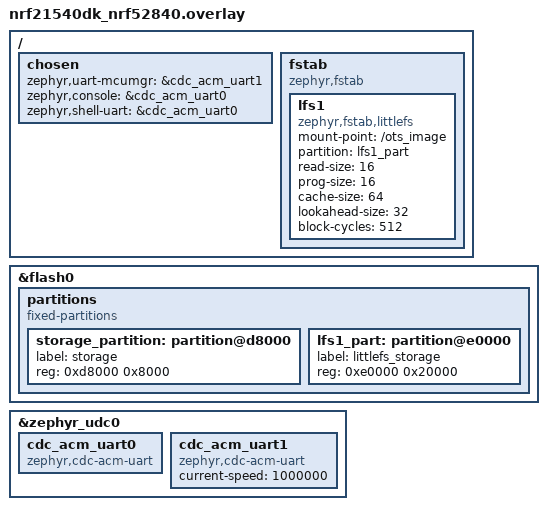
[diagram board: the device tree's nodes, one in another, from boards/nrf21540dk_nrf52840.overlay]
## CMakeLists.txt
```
#
# Copyright (c) 2022 Nordic Semiconductor
#
# SPDX-License-Identifier: LicenseRef-Nordic-5-Clause
#

cmake_minimum_required(VERSION 3.20.0)

# The application uses the conf/<board> scheme for configuration files.
#set(APPLICATION_CONFIG_DIR "${CMAKE_CURRENT_SOURCE_DIR}/conf/\${BOARD}")

set(PM_STATIC_YML_FILE
  #"${CMAKE_CURRENT_SOURCE_DIR}/conf/\${BOARD}/pm_static_${BOARD}.yml"
   ${CMAKE_CURRENT_SOURCE_DIR}/boards/pm_static_${BOARD}.yml
  )

list(APPEND hci_rpmsg_b0n_OVERLAY_CONFIG overlay-minimal-size.conf)

find_package(Zephyr REQUIRED HINTS $ENV{ZEPHYR_BASE})
project(central_esl)

# NORDIC SDK APP START
target_sources(app PRIVATE
  src/main.c
)

# Add ESLS Client source
zephyr_library_sources_ifdef(
  CONFIG_BT_ESL_CLIENT
  ../service/esl_client.c
  ../service/esl_client_settings.c
  ../service/esl_common.c)

zephyr_library_sources_ifdef(
  CONFIG_ESL_CLIENT_SHELL
  ../service/esl_client_shell.c
  ../service/esl_dummy_cmd.c)
zephyr_library_sources_ifdef(CONFIG_BT_ESL_TAG_STORAGE  ../service/esl_client_tag_storage.c)

zephyr_library_include_directories_ifdef(CONFIG_BT_ESL_CLIENT ../service)
target_include_directories(app PRIVATE   ${ZEPHYR_BASE}/subsys/bluetooth/host)

# NORDIC SDK APP END

zephyr_library_include_directories(.)
```

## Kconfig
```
#
# Copyright (c) 2022 Nordic Semiconductor
#
# SPDX-License-Identifier: LicenseRef-Nordic-5-Clause
#

source "Kconfig.zephyr"

menu "Nordic ESL BLE GATT service client"

config BT_ESL_CLIENT_THREAD_STACK_SIZE
	int "Thread stack size"
	default 1024
	help
	  Stack size used in each of the two threads

config BT_ESL_SECURITY_ENABLED
	bool "Enable security"
	select BT_SMP
	select BT_BONDABLE
	select BT_BONDING_REQUIRED
	help
	  "Enable BLE security for the ESL service"

config BT_ESL_AP_AUTO_MODE
	bool "AP auto onboarding Tag mode"
	help
	  "Enable,AP will auto scan and configure tag. Disable,AP will only accept shell command"

if BT_ESL_AP_AUTO_MODE
config BT_ESL_AP_AUTO_TAG_PER_GROUP
	int "Tag per group"
	default ESL_CLIENT_MAX_RESPONSE_SLOT_BUFFER
	help
	  "How many tags should keep in same group for auto onboarding.
	   Tag number exceeds this number should be in next group.
	   Otherwise, response key is not enough for all tags in same group.
	   How to choose this number depends on what scenario we want to show.
	   Less or equal to ESL_CLIENT_MAX_RESPONSE_SLOT_BUFFER demostrates decrypts response EAD on-the-fly.
	   Greater than ESL_CLIENT_MAX_RESPONSE_SLOT_BUFFER demostrates ESL AP able to control large amount of tags at the same time."

config BT_ESL_AP_GROUP_PER_BUTTON
	int "Group per button"
	default 3
	help
	  "How many groups should be controlled by one button.
	   If this number is greater than 1, AP will control multiple groups by one button.
	   Otherwise, AP will control one group by one button."
endif

config BT_ESL_AP_AUTO_PAST_TAG
	bool "AP auto past mode"
	help
	  "Enable,AP will auto send update complete command and PAST to unsynchronized tag. Disable,AP will only accept shell command"

config BT_ESL_AP_PTS
	bool "ESL access point for PTS test"
	help
	  Enable PTS test for ESL access point

module = CENTRAL_ESL
module-str = central esl
source "${ZEPHYR_BASE}/subsys/logging/Kconfig.template.log_config"
endmenu

rsource "../service/Kconfig.esl_client"
```

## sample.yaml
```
sample:
  name: BLE ESL AP
  description: Bluetooth Low Energy ESL Access Point application
tests:
  applications.bluetooth.central_esl:
    build_only: true
    platform_allow: nrf52840dk_nrf52840 nrf5340dk_nrf5340_cpuapp thingy53_nrf5340_cpuapp
    integration_platforms:
      - nrf52840dk_nrf52840
      - nrf5340dk_nrf5340_cpuapp
      - thingy53_nrf5340_cpuapp
    tags: bluetooth ci_build
```

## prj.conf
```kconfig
#
# Copyright (c) 2022 Nordic Semiconductor
#
# SPDX-License-Identifier: LicenseRef-Nordic-5-Clause
#

CONFIG_DK_LIBRARY=y
CONFIG_NEWLIB_LIBC=y
CONFIG_GPIO=y

# Enable the UART driver
CONFIG_CONSOLE=y
CONFIG_UART_CONSOLE=y

# Enable the BLE stack with GATT Client configuration
CONFIG_BT=y
CONFIG_BT_CENTRAL=y
CONFIG_BT_PERIPHERAL=n
CONFIG_BT_GATT_CLIENT=y
CONFIG_BT_MAX_CONN=4
CONFIG_BT_MAX_PAIRED=4

# Enable ESL Client modules
CONFIG_BT_ESL_CLIENT=y
CONFIG_BT_ESL_AP_AUTO_MODE=y
CONFIG_BT_ESL_DEMO_SECURITY=n

CONFIG_BT_ESL_SECURITY_ENABLED=y
CONFIG_BT_ESL_AP_AUTO_PAST_TAG=y

# Enable the BLE modules from NCS
CONFIG_BT_SCAN=y
CONFIG_BT_SCAN_FILTER_ENABLE=y
CONFIG_BT_SCAN_UUID_CNT=1
CONFIG_BT_GATT_DM=y
CONFIG_HEAP_MEM_POOL_SIZE=4096
CONFIG_BT_SCAN_ADDRESS_CNT=16

# Enable EATT for multi read/write request
CONFIG_BT_L2CAP_ECRED=y
CONFIG_BT_EATT=y
CONFIG_BT_ATT_PREPARE_COUNT=32
CONFIG_BT_EATT_MAX=16
CONFIG_BT_GATT_AUTO_SEC_REQ=n
CONFIG_BT_EATT_AUTO_CONNECT=n
CONFIG_BT_GATT_SERVICE_CHANGED=n
CONFIG_BT_GATT_DYNAMIC_DB=n

CONFIG_BT_L2CAP_TX_MTU=498
CONFIG_BT_OTS_L2CAP_CHAN_TX_MTU=498
# This example requires more workqueue stack
CONFIG_SYSTEM_WORKQUEUE_STACK_SIZE=4096

# Settings need more memory
CONFIG_MAIN_STACK_SIZE=2048

# Enable bonding
CONFIG_BT_SETTINGS=y
CONFIG_FLASH=y
CONFIG_FLASH_PAGE_LAYOUT=y
CONFIG_FLASH_MAP=y
CONFIG_NVS=y
CONFIG_BT_BONDABLE=y
CONFIG_BT_ESL_TAG_STORAGE=y

# Bluetooth L2CAP parameter
CONFIG_BT_L2CAP_TX_BUF_COUNT=12

# LOG
CONFIG_LOG=y
CONFIG_LOG_BACKEND_UART=n
CONFIG_SHELL_LOG_BACKEND=n
CONFIG_USE_SEGGER_RTT=y
CONFIG_LOG_BACKEND_RTT=y
CONFIG_LOG_BUFFER_SIZE=8192
CONFIG_LOG_BACKEND_RTT_MODE_DROP=n
CONFIG_LOG_PRINTK=n
CONFIG_SEGGER_RTT_BUFFER_SIZE_UP=8192

# SHELL
CONFIG_SHELL_PROMPT_UART="ESL_AP:~$ "
CONFIG_SHELL_STACK_SIZE=4096
CONFIG_ESL_CLIENT_SHELL=y
CONFIG_SHELL_ARGC_MAX=48
CONFIG_SHELL_BACKEND_SERIAL_TX_RING_BUFFER_SIZE=24

# Periodic Adv
CONFIG_BT_EXT_ADV=y
CONFIG_BT_PER_ADV=y
CONFIG_BT_LOG_SNIFFER_INFO=y
CONFIG_BT_EXT_ADV_LEGACY_SUPPORT=y
CONFIG_BT_PER_ADV_SYNC=y
CONFIG_BT_DEVICE_NAME="ESL_AP"
CONFIG_BT_EXT_ADV_MAX_ADV_SET=1

CONFIG_BT_AUTO_PHY_UPDATE=n
CONFIG_BT_BUF_CMD_TX_COUNT=20
CONFIG_ESL_CLIENT_DEFAULT_ESL_ID=0
CONFIG_ESL_CLIENT_DEFAULT_GROUP_ID=0
CONFIG_BT_ESL_MAX_QUEUED_TIMED_COMMANDS=1

# Enable mcumgr
CONFIG_ZCBOR=y
CONFIG_MCUMGR=y
# Required by the `taskstat` command
CONFIG_THREAD_MONITOR=y
# USB backend is serial device
CONFIG_BASE64=y
CONFIG_MCUMGR_TRANSPORT_UART=y
CONFIG_USB_CDC_ACM_LOG_LEVEL_OFF=y
# Support for taskstat command
CONFIG_MCUMGR_GRP_OS_TASKSTAT=y

# Enable statistics and statistic names
CONFIG_STATS=y
CONFIG_STATS_NAMES=y

# Enable most core commands
CONFIG_STREAM_FLASH=y
CONFIG_IMG_MANAGER=y
CONFIG_MCUMGR_GRP_IMG=y
CONFIG_MCUMGR_GRP_OS=y
CONFIG_MCUMGR_GRP_STAT=y
# Enable file system commands
CONFIG_MCUMGR_GRP_FS=y

# Debug
CONFIG_BT_ESL_CLIENT_LOG_LEVEL_INF=y
CONFIG_CENTRAL_ESL_LOG_LEVEL_INF=y
# CONFIG_BT_USE_DEBUG_KEYS=y
# CONFIG_BT_STORE_DEBUG_KEYS=y

CONFIG_BT_KEYS_OVERWRITE_OLDEST=y
# Response slot 8 need 546 bytes to accept response key
# CONFIG_SHELL_BACKEND_SERIAL_RX_RING_BUFFER_SIZE=546
# CONFIG_SHELL_CMD_BUFF_SIZE=546
# Response slot 12 need 742 bytes to accept response key
# CONFIG_SHELL_BACKEND_SERIAL_RX_RING_BUFFER_SIZE=742
# CONFIG_SHELL_CMD_BUFF_SIZE=742
# Response slot 23 need 1282 bytes to accept response key
CONFIG_SHELL_BACKEND_SERIAL_RX_RING_BUFFER_SIZE=1282
CONFIG_SHELL_CMD_BUFF_SIZE=1282
CONFIG_SETTINGS_SHELL=y
CONFIG_SHELL_LOG_BACKEND=n
CONFIG_DEVICE_SHELL=n
CONFIG_DEVMEM_SHELL=n
CONFIG_FLASH_SHELL=n
CONFIG_BT_DEBUG_LOG=y
CONFIG_BT_DEBUG_HCI_CORE=n
CONFIG_BT_DEBUG_HCI_DRIVER=n
CONFIG_BT_GATT_DM_LOG_LEVEL_DBG=n
CONFIG_BT_GATT_DM_MAX_ATTRS=256
CONFIG_BT_DEBUG_GATT=n
CONFIG_ASSERT=n

# BTMON hci log start
# CONFIG_BT_DEBUG_MONITOR_UART=y
# CONFIG_UART_CONSOLE=n
# BTMON hci log end
```

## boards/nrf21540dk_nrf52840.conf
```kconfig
#
# Copyright (c) 2023 Nordic Semiconductor ASA
#
# SPDX-License-Identifier: LicenseRef-Nordic-5-Clause
#

# External Flash for TAG OTS image storage
# Need this when storage is on flash
CONFIG_MPU_ALLOW_FLASH_WRITE=y

CONFIG_FLASH=y
CONFIG_FLASH_MAP=y
CONFIG_FLASH_PAGE_LAYOUT=y
CONFIG_FILE_SYSTEM=y
CONFIG_FILE_SYSTEM_LITTLEFS=y
CONFIG_FILE_SYSTEM_SHELL=y
CONFIG_RESET_ON_FATAL_ERROR=n
CONFIG_ESL_CLIENT_MAX_GROUP=64

# ESL AP two CDC uart, one for command, one for SMP
CONFIG_USB_DEVICE_STACK=y
CONFIG_USB_DEVICE_PRODUCT="Nordic ESL Access Point"
CONFIG_UART_LINE_CTRL=y

# LOG
# CONFIG_MCUBOOT_UTIL_LOG_LEVEL_WRN=y
# CONFIG_MCUMGR_LOG_LEVEL_DBG=y
# CONFIG_BT_DEBUG_OTS_CLIENT=y
# CONFIG_BT_OTS_CLIENT_LOG_LEVEL_DBG=y

# PAWR timing
CONFIG_BT_CTLR_SDC_PAWR_ADV_COUNT=1
CONFIG_BT_CTLR_SDC_PERIODIC_ADV_RSP_TX_BUFFER_COUNT=3
CONFIG_BT_CTLR_SDC_PERIODIC_ADV_RSP_RX_BUFFER_COUNT=12
CONFIG_BT_PER_ADV_SYNC_MAX=1
CONFIG_BT_CTLR_SDC_MAX_CONN_EVENT_LEN_DEFAULT=2500
CONFIG_BT_BUF_ACL_RX_SIZE=502
CONFIG_BT_BUF_CMD_TX_SIZE=255
CONFIG_BT_BUF_EVT_DISCARDABLE_SIZE=255
CONFIG_BT_CTLR_SDC_PERIPHERAL_COUNT=0
CONFIG_BT_CTLR_ADV_DATA_LEN_MAX=73
CONFIG_BT_CTLR_TX_PWR_PLUS_8=y
```

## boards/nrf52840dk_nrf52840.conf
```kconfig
#
# Copyright (c) 2023 Nordic Semiconductor ASA
#
# SPDX-License-Identifier: LicenseRef-Nordic-5-Clause
#

# External Flash for TAG OTS image storage
# Need this when storage is on flash
CONFIG_MPU_ALLOW_FLASH_WRITE=y

# Need this when storage is on MX25R64 QSPI
CONFIG_NORDIC_QSPI_NOR=y
CONFIG_NORDIC_QSPI_NOR_FLASH_LAYOUT_PAGE_SIZE=4096
CONFIG_FLASH=y
CONFIG_FLASH_MAP=y
CONFIG_FLASH_PAGE_LAYOUT=y
CONFIG_FILE_SYSTEM=y
CONFIG_FILE_SYSTEM_LITTLEFS=y
CONFIG_PM_PARTITION_REGION_LITTLEFS_EXTERNAL=y
CONFIG_PM_PARTITION_SIZE_LITTLEFS=0x300000
CONFIG_FILE_SYSTEM_SHELL=y
CONFIG_RESET_ON_FATAL_ERROR=n
CONFIG_ESL_CLIENT_MAX_GROUP=64

# ESL AP two CDC uart, one for command, one for SMP
CONFIG_USB_DEVICE_STACK=y
CONFIG_USB_DEVICE_PRODUCT="Nordic ESL Access Point"
CONFIG_UART_LINE_CTRL=y

# Ensure an MCUboot-compatible binary is generated
CONFIG_BOOTLOADER_MCUBOOT=y

# LOG
# CONFIG_MCUBOOT_UTIL_LOG_LEVEL_WRN=y
# CONFIG_MCUMGR_LOG_LEVEL_DBG=y
# CONFIG_BT_DEBUG_OTS_CLIENT=y
# CONFIG_BT_OTS_CLIENT_LOG_LEVEL_DBG=y

# PAWR timing
CONFIG_BT_CTLR_SDC_PAWR_ADV_COUNT=1
CONFIG_BT_CTLR_SDC_PERIODIC_ADV_RSP_TX_BUFFER_COUNT=3
CONFIG_BT_CTLR_SDC_PERIODIC_ADV_RSP_RX_BUFFER_COUNT=12
CONFIG_BT_PER_ADV_SYNC_MAX=1
CONFIG_BT_CTLR_SDC_MAX_CONN_EVENT_LEN_DEFAULT=2500
CONFIG_BT_BUF_ACL_RX_SIZE=502
CONFIG_BT_BUF_CMD_TX_SIZE=255
CONFIG_BT_BUF_EVT_DISCARDABLE_SIZE=255
CONFIG_BT_CTLR_SDC_PERIPHERAL_COUNT=0
CONFIG_BT_CTLR_ADV_DATA_LEN_MAX=73
CONFIG_BT_CTLR_TX_PWR_PLUS_8=y
```

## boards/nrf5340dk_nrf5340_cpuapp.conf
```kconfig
#
# Copyright (c) 2023 Nordic Semiconductor ASA
#
# SPDX-License-Identifier: LicenseRef-Nordic-5-Clause
#

# External Flash for TAG OTS image storage
# Need this when storage is on flash
CONFIG_MPU_ALLOW_FLASH_WRITE=y

# Need this when storage is on MX25R64 QSPI
CONFIG_NORDIC_QSPI_NOR=y
CONFIG_NORDIC_QSPI_NOR_FLASH_LAYOUT_PAGE_SIZE=4096
CONFIG_FLASH=y
CONFIG_FLASH_MAP=y
CONFIG_FLASH_PAGE_LAYOUT=y
CONFIG_FILE_SYSTEM=y
CONFIG_FILE_SYSTEM_LITTLEFS=y
CONFIG_PM_PARTITION_REGION_LITTLEFS_EXTERNAL=y
CONFIG_PM_PARTITION_SIZE_LITTLEFS=0x300000
CONFIG_FILE_SYSTEM_SHELL=y
CONFIG_RESET_ON_FATAL_ERROR=n

# ESL AP two CDC uart, one for command, one for SMP
CONFIG_USB_DEVICE_STACK=y
CONFIG_USB_DEVICE_PRODUCT="Nordic ESL Access Point"
CONFIG_UART_LINE_CTRL=y

# Ensure an MCUboot-compatible binary is generated
CONFIG_BOOTLOADER_MCUBOOT=y

# LOG
# CONFIG_MCUBOOT_UTIL_LOG_LEVEL_WRN=y
# CONFIG_MCUMGR_LOG_LEVEL_DBG=y
# CONFIG_BT_DEBUG_OTS_CLIENT=y
# CONFIG_BT_OTS_CLIENT_LOG_LEVEL_DBG=y
```

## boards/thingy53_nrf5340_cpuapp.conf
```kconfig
#
# Copyright (c) 2023 Nordic Semiconductor ASA
#
# SPDX-License-Identifier: LicenseRef-Nordic-5-Clause
#

# External Flash for TAG OTS image storage
# Need this when storage is on flash
CONFIG_MPU_ALLOW_FLASH_WRITE=y

# Need this when storage is on MX25R64 QSPI
CONFIG_NORDIC_QSPI_NOR=y
CONFIG_NORDIC_QSPI_NOR_FLASH_LAYOUT_PAGE_SIZE=4096
CONFIG_FLASH=y
CONFIG_FLASH_MAP=y
CONFIG_FLASH_PAGE_LAYOUT=y
CONFIG_FILE_SYSTEM=y
CONFIG_FILE_SYSTEM_LITTLEFS=y
CONFIG_FILE_SYSTEM_SHELL=y
CONFIG_RESET_ON_FATAL_ERROR=n

# ESL AP two CDC uart, one for command, one for SMP
CONFIG_USB_DEVICE_STACK=y
CONFIG_USB_DEVICE_PRODUCT="Nordic ESL Access Point"
CONFIG_UART_LINE_CTRL=y
CONFIG_USB_DEVICE_INITIALIZE_AT_BOOT=y

# # Ensure an MCUboot-compatible binary is generated
CONFIG_BOOTLOADER_MCUBOOT=y

# Enable logging
# CONFIG_MCUBOOT_UTIL_LOG_LEVEL_WRN=y
# CONFIG_MCUMGR_LOG_LEVEL_DBG=y
# CONFIG_BT_DEBUG_OTS_CLIENT=y
# CONFIG_BT_OTS_CLIENT_LOG_LEVEL_DBG=y
```

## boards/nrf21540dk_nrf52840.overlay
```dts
 / {
	chosen {
		zephyr,uart-mcumgr = &cdc_acm_uart1;
		zephyr,console = &cdc_acm_uart0;
		zephyr,shell-uart = &cdc_acm_uart0;
	};
};

/delete-node/ &storage_partition;
/ {
	fstab {
		compatible = "zephyr,fstab";
		lfs1: lfs1 {
			compatible = "zephyr,fstab,littlefs";
			mount-point = "/ots_image";
			partition = <&lfs1_part>;
			read-size = <16>;
			prog-size = <16>;
			cache-size = <64>;
			lookahead-size = <32>;
			block-cycles = <512>;
		};
	};
};


&flash0 {
	partitions {
		compatible = "fixed-partitions";
		#address-cells = <1>;
		#size-cells = <1>;
		storage_partition: partition@d8000 {
			label = "storage";
			reg = < 0xd8000 0x8000 >;
		};
		lfs1_part: partition@e0000 {
			label = "littlefs_storage";
			reg = <0xe0000 0x20000>;
		};
	};
};


&zephyr_udc0 {
	cdc_acm_uart0: cdc_acm_uart0 {
		compatible = "zephyr,cdc-acm-uart";
	};

	cdc_acm_uart1: cdc_acm_uart1 {
		current-speed=<1000000>;
		compatible = "zephyr,cdc-acm-uart";
	};

};
```

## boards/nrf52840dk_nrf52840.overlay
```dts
/ {
	chosen {
		nordic,pm-ext-flash = &mx25r64;
		zephyr,uart-mcumgr = &cdc_acm_uart1;
		zephyr,console = &cdc_acm_uart0;
		zephyr,shell-uart = &cdc_acm_uart0;
	};
};

/ {
	fstab {
		compatible = "zephyr,fstab";
		lfs1: lfs1 {
			compatible = "zephyr,fstab,littlefs";
			mount-point = "/ots_image";
			partition = <&lfs1_part>;
			read-size = <16>;
			prog-size = <16>;
			cache-size = <64>;
			lookahead-size = <32>;
			block-cycles = <512>;
		};
	};
};

&mx25r64 {
	partitions {
		compatible = "fixed-partitions";
		#address-cells = <1>;
		#size-cells = <1>;

		lfs1_part: partition@0 {
			label = "littlefs_storage";
			reg = <0x00000000 0x00100000>;
		};
	};
};

&zephyr_udc0 {
	cdc_acm_uart0: cdc_acm_uart0 {
		compatible = "zephyr,cdc-acm-uart";
	};

	cdc_acm_uart1: cdc_acm_uart1 {
		current-speed=<1000000>;
		compatible = "zephyr,cdc-acm-uart";
	};

};
```

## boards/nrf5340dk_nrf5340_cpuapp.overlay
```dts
/ {
	chosen {
		nordic,pm-ext-flash = &mx25r64;
		zephyr,uart-mcumgr = &cdc_acm_uart1;
		zephyr,console = &cdc_acm_uart0;
		zephyr,shell-uart = &cdc_acm_uart0;
	};
};

&zephyr_udc0 {
	cdc_acm_uart0: cdc_acm_uart0 {
		compatible = "zephyr,cdc-acm-uart";
	};

	cdc_acm_uart1: cdc_acm_uart1 {
		current-speed=<1000000>;
		compatible = "zephyr,cdc-acm-uart";
	};

};
```

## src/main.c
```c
/*
 * Copyright (c) 2023 Nordic Semiconductor ASA
 *
 * SPDX-License-Identifier: LicenseRef-Nordic-5-Clause
 */

/** @file
 *  @brief Nordic ESL Service Client Application
 */

#include <errno.h>
#include <zephyr/kernel.h>
#include <zephyr/sys/byteorder.h>
#include <zephyr/sys/printk.h>

#include <zephyr/bluetooth/bluetooth.h>
#include <zephyr/bluetooth/hci.h>
#include <zephyr/bluetooth/conn.h>
#include <zephyr/bluetooth/uuid.h>
#include <zephyr/bluetooth/gatt.h>
#include <zephyr/sys/slist.h>
#include <zephyr/settings/settings.h>
#include <zephyr/logging/log.h>
#include <zephyr/usb/usb_device.h>
#include <bluetooth/gatt_dm.h>
#include <bluetooth/scan.h>
#include <dk_buttons_and_leds.h>

#include "esl_client.h"

LOG_MODULE_REGISTER(central_esl, CONFIG_CENTRAL_ESL_LOG_LEVEL);

static struct bt_esl_client esl_client;

#ifdef CONFIG_MCUMGR_GRP_FS
#include <zephyr/device.h>
#include <zephyr/fs/fs.h>
#include <zephyr/fs/littlefs.h>

#define PARTITION_NODE DT_NODELABEL(lfs1)

#if DT_NODE_EXISTS(PARTITION_NODE)
/* Internal flash use DTS partition */
FS_FSTAB_DECLARE_ENTRY(PARTITION_NODE);
#else
/* External flash use PM partition */
#define STORAGE_PARTITION_LABEL littlefs_storage
#define STORAGE_PARTITION_ID	FIXED_PARTITION_ID(STORAGE_PARTITION_LABEL)

FS_LITTLEFS_DECLARE_DEFAULT_CONFIG(cstorage);
static struct fs_mount_t pm_littlefs_mnt = {.type = FS_LITTLEFS,
					    .fs_data = &cstorage,
					    .storage_dev = (void *)STORAGE_PARTITION_ID,
					    .mnt_point = MNT_POINT};
#endif /* (DT_NODE_EXISTS(PARTITION_NODE)) */
struct fs_mount_t *mp =
#if DT_NODE_EXISTS(PARTITION_NODE)
	&FS_FSTAB_ENTRY(PARTITION_NODE)
#else
	&pm_littlefs_mnt
#endif /* (DT_NODE_EXISTS(PARTITION_NODE)*/
	;
#endif /* (CONFIG_MCUMGR_GRP_FS) */
int ap_image_storage_init(void)
{
	int err = 0;
#ifdef CONFIG_MCUMGR_GRP_FS
	err = fs_mount(mp);
	if (err < 0) {
		LOG_ERR("Error mounting littlefs [%d]", err);
	}
#if defined(CONFIG_BT_ESL_TAG_STORAGE)
	struct fs_dir_t dirp;

	load_all_tags_in_storage(BIT(ESL_GROUPID_RFU_BIT));

	/* Check if TAG_BLE_ADDR_ROOT exists */
	fs_dir_t_init(&dirp);
	err = fs_opendir(&dirp, TAG_BLE_ADDR_ROOT);
	if (err) {
		err = fs_mkdir(TAG_BLE_ADDR_ROOT);
		if (err) {
			LOG_ERR("Create TAG_BLE_ADDR_ROOT dir failed (ret %d)", err);
			err = -EIO;
		}
	}

	fs_closedir(&dirp);

	/* Check if TAG_ESL_ADDR_ROOT exists */
	fs_dir_t_init(&dirp);
	err = fs_opendir(&dirp, TAG_ESL_ADDR_ROOT);
	if (err) {
		err = fs_mkdir(TAG_ESL_ADDR_ROOT);
		if (err) {
			LOG_ERR("Create TAG_ESL_ADDR_ROOT dir failed (ret %d)", err);
			err = -EIO;
		}
	}

	fs_closedir(&dirp);

#endif /* (CONFIG_BT_ESL_TAG_STORAGE) */

#else
	LOG_ERR("No valid image storage");
	err = -ENXIO;
#endif /* (CONFIG_MCUMGR_GRP_FS) */
	return err;
}

ssize_t ap_read_img_size_from_storage(uint8_t *img_path)
{
	int ret = 0;
#ifdef CONFIG_MCUMGR_GRP_FS
	/* Here demostrates how to retrieve image size from littlefs */
	struct fs_dirent dirent;
	struct fs_file_t file;
	int rc;

	fs_file_t_init(&file);
	rc = fs_open(&file, img_path, FS_O_CREATE | FS_O_RDWR);
	if (rc < 0) {
		LOG_ERR("FAIL: open %s: %d", img_path, rc);
		return 0;
	}

	rc = fs_stat(img_path, &dirent);
	if (rc < 0) {
		LOG_ERR("FAIL: stat %s: %d", img_path, rc);
		return 0;
	}

	LOG_INF("%s img_path size %d", img_path, dirent.size);
	ret = dirent.size;
	(void)fs_close(&file);
#else
	LOG_ERR("No valid image");
#endif
	return ret;
}

int ap_read_img_from_storage(uint8_t *img_path, void *data, size_t *len)
{
	int ret;
#ifdef CONFIG_MCUMGR_GRP_FS
	/* Here demostrates how to retrieve image from littlefs */
	struct fs_dirent dirent;
	struct fs_file_t file;
	int rc;

	fs_file_t_init(&file);
	rc = fs_open(&file, img_path, FS_O_CREATE | FS_O_RDWR);
	if (rc < 0) {
		LOG_ERR("FAIL: open %s: %d", img_path, rc);
		return rc;
	}

	rc = fs_stat(img_path, &dirent);
	if (rc < 0) {
		LOG_ERR("FAIL: stat %s: %d", img_path, rc);
		goto out;
	}

	if (rc == 0 && dirent.type == FS_DIR_ENTRY_FILE && dirent.size == 0) {
		LOG_ERR("Image file: %s not found", img_path);
		ret = -ENXIO;
	}

	LOG_INF("%s img_path size %d", img_path, dirent.size);
	rc = fs_read(&file, data, dirent.size);
	if (rc < 0) {
		LOG_ERR("FAIL: read %s: [rd:%d]", img_path, rc);
		goto out;
	}

	*len = rc;
out:
	ret = fs_close(&file);
	if (ret < 0) {
		LOG_ERR("FAIL: close %s: %d", img_path, ret);
		return ret;
	}

	return (rc < 0 ? rc : 0);

#else
	LOG_ERR("No valid image");
	ret = -ENXIO;
	return ret;
#endif /* (CONFIG_MCUMGR_GRP_FS) */
}

static int esl_client_init(void)
{
	int err;
	struct bt_esl_client_init_param init;

	init.cb.ap_image_storage_init = ap_image_storage_init;
	init.cb.ap_read_img_from_storage = ap_read_img_from_storage;
	init.cb.ap_read_img_size_from_storage = ap_read_img_size_from_storage;
	err = bt_esl_client_init(&esl_client, &init);
	if (err) {
		LOG_ERR("ESL Client initialization failed (err %d)", err);
		return err;
	}

	LOG_INF("ESL Client module initialized");
	return err;
}

static void auth_cancel(struct bt_conn *conn)
{
	char addr[BT_ADDR_LE_STR_LEN];

	bt_addr_le_to_str(bt_conn_get_dst(conn), addr, sizeof(addr));

	LOG_INF("Pairing cancelled: %s", addr);
}

static void pairing_complete(struct bt_conn *conn, bool bonded)
{
	char addr[BT_ADDR_LE_STR_LEN];

	bt_addr_le_to_str(bt_conn_get_dst(conn), addr, sizeof(addr));

	LOG_INF("Pairing completed: %s, bonded: %d", addr, bonded);
}

static void pairing_failed(struct bt_conn *conn, enum bt_security_err reason)
{
	char addr[BT_ADDR_LE_STR_LEN];

	bt_addr_le_to_str(bt_conn_get_dst(conn), addr, sizeof(addr));

	LOG_WRN("Pairing failed conn: %s, reason %d", addr, reason);
	bt_conn_disconnect(conn, BT_HCI_ERR_AUTH_FAIL);
}

void bond_deleted(uint8_t id, const bt_addr_le_t *peer)
{
	char addr[BT_ADDR_STR_LEN];

	bt_addr_le_to_str(peer, addr, sizeof(addr));
	LOG_INF("Bond deleted for %s, id %u", addr, id);
}

static struct bt_conn_auth_cb conn_auth_callbacks = {.cancel = auth_cancel};

static struct bt_conn_auth_info_cb conn_auth_info_callbacks = {.pairing_complete = pairing_complete,
							       .pairing_failed = pairing_failed,
							       .bond_deleted = bond_deleted

};

extern uint8_t groups_per_button;
static uint8_t btn3_toggle;
static uint8_t btn3_group_toggle;
static uint8_t btn4_toggle;
static uint8_t btn4_group_toggle;
/**
 *  type 0x07 broadcast Display Img 0
 *  type 0x08 broadcast Display Img 1
 *  type 0X12 Tag 0~10 Display Img 0
 *  type 0X13 Tag 0~10 Display img 1
 **/
static uint8_t btn3_cmd_list[] = {0x7, 0x8, 0x12, 0x13};

/**
 * type 1 led 0 broadcast flashing
 * type 4 led 0 broadcast off
 */
static uint8_t btn4_cmd_list[] = {0x1, 0x4};
static void button_handler(uint32_t button_state, uint32_t has_changed)
{
	uint32_t button = button_state & has_changed;

	if (button & DK_BTN1_MSK) {
		esl_c_scan(true, false);
	}

	if (button & DK_BTN2_MSK) {
#if defined(CONFIG_BT_ESL_TAG_STORAGE)
		bt_c_esl_unbond(-1);
		remove_all_tags_in_storage();
#endif
	}

	if (button & DK_BTN3_MSK) {
		esl_dummy_ap_ad_data(btn3_cmd_list[btn3_toggle % sizeof(btn3_cmd_list)],
				     btn3_group_toggle);
		printk("btn3_group_toggle %d\n", btn3_group_toggle);
		btn3_toggle++;
		btn3_group_toggle = (btn3_toggle / sizeof(btn3_cmd_list)) % groups_per_button;
	}

	if (button & DK_BTN4_MSK) {
		esl_dummy_ap_ad_data(btn4_cmd_list[btn4_toggle % sizeof(btn4_cmd_list)],
				     btn4_group_toggle);
		printk("btn4_group_toggle %d\n", btn4_group_toggle);
		btn4_toggle++;
		btn4_group_toggle = (btn4_toggle / sizeof(btn4_cmd_list)) % groups_per_button;
	}
}

int main(void)
{
	int err;
	uint16_t ctrl_version = 0;

	err = dk_buttons_init(button_handler);
	if (err) {
		LOG_ERR("Failed to init dk buttons. %d", err);
		return err;
	}

	if (IS_ENABLED(CONFIG_USB_DEVICE_STACK)) {
		err = usb_enable(NULL);
		if (err) {
			LOG_ERR("Failed to init usb %d", err);
		}
	}

	err = bt_conn_auth_cb_register(&conn_auth_callbacks);
	if (err) {
		LOG_ERR("Failed to register authorization callbacks. %d", err);
		return err;
	}

	err = bt_conn_auth_info_cb_register(&conn_auth_info_callbacks);
	if (err) {
		LOG_ERR("Failed to register authorization callbacks. %d", err);
		return err;
	}

#if defined(BT_ESL_AP_PTS)
	uint8_t pub_addr[] = {0xBB, 0xBB, 0xBB, 0xBB, 0xBB, 0xBB};

	bt_ctlr_set_public_addr(pub_addr);
#endif /* CONFIG_BT_ESL_AP_PTS */

	err = bt_enable(NULL);
	if (IS_ENABLED(CONFIG_SETTINGS)) {
		settings_load();
	}

	err = ble_ctrl_version_get(&ctrl_version);
	if (err != 0) {
		LOG_ERR("Failed to get controller version");
	}

	printk("Controller version: %d\n", ctrl_version);
	esl_client_init();
	int (*module_init[])(void) = {esl_client.cb.ap_image_storage_init};

	for (size_t i = 0; i < ARRAY_SIZE(module_init); i++) {
		err = (*module_init[i])();
		if (err) {
			LOG_ERR("init module %d (err %d)", i, err);
			return err;
		}
	}

	LOG_INF("Starting Bluetooth Central ESL example\n");
	for (;;) {
		/* Wait infinitely */
		k_sleep(K_FOREVER);
	}
}
```
